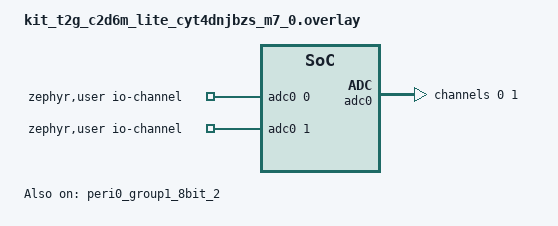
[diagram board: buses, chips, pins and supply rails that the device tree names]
/*
 * SPDX-FileCopyrightText: Copyright (c) 2026 Linumiz
 *
 * SPDX-License-Identifier: Apache-2.0
 */

#include <zephyr/dt-bindings/adc/adc.h>

/ {
	zephyr,user {
		io-channels = <&adc0 0>, <&adc0 1>;
	};
};

&peri0_group1_8bit_2 {
	status = "okay";
};

&adc0 {
	#address-cells = <1>;
	#size-cells = <0>;
	clocks = <&peri0_group1_8bit_2>;
	clock-frequency = <25000000>;
	status = "okay";

	channel@0 {
		reg = <0>;
		zephyr,gain = "ADC_GAIN_1";
		zephyr,reference = "ADC_REF_VDD_1";
		zephyr,input-positive = <14>;
		zephyr,acquisition-time = <ADC_ACQ_TIME(ADC_ACQ_TIME_MICROSECONDS, 10)>;
		zephyr,resolution = <12>;
	};

	channel@1 {
		reg = <1>;
		zephyr,gain = "ADC_GAIN_1";
		zephyr,reference = "ADC_REF_VDD_1";
		zephyr,input-positive = <15>;
		zephyr,acquisition-time = <ADC_ACQ_TIME(ADC_ACQ_TIME_MICROSECONDS, 10)>;
		zephyr,resolution = <12>;
	};
};
